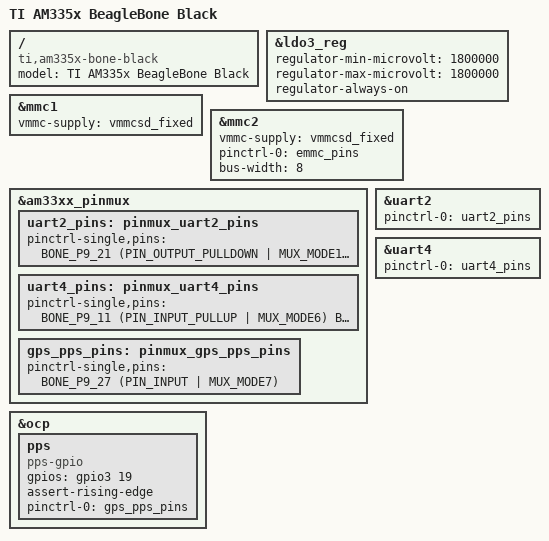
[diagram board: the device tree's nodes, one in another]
/dts-v1/;

#include "am33xx.dtsi"
#include "am335x-bone-common.dtsi"
#include <dt-bindings/board/am335x-bbw-bbb-base.h>
#include <dt-bindings/pinctrl/am33xx.h>

/ {
	model = "TI AM335x BeagleBone Black";
	compatible = "ti,am335x-bone-black", "ti,am335x-bone", "ti,am33xx";
};

&ldo3_reg {
	regulator-min-microvolt = <1800000>;
	regulator-max-microvolt = <1800000>;
	regulator-always-on;
};

&mmc1 {
	vmmc-supply = <&vmmcsd_fixed>;
};

&mmc2 {
	vmmc-supply = <&vmmcsd_fixed>;
	pinctrl-names = "default";
	pinctrl-0 = <&emmc_pins>;
	bus-width = <8>;
	status = "okay";
};

&am33xx_pinmux {

	uart2_pins: pinmux_uart2_pins {
		pinctrl-single,pins = <
			BONE_P9_21 (PIN_OUTPUT_PULLDOWN | MUX_MODE1) /* spi0_d0.uart2_txd */
			BONE_P9_22 (PIN_INPUT_PULLUP | MUX_MODE1) /* spi0_sclk.uart2_rxd */
			BONE_P8_38 (PIN_OUTPUT | MUX_MODE6)	/* lcd_data9.uart2_rtsn */
			BONE_P8_37 (PIN_INPUT  | MUX_MODE6)	/* lcd_data8.uart2_ctsn */
		>;
	};

	uart4_pins: pinmux_uart4_pins {
		pinctrl-single,pins = <
			BONE_P9_11 (PIN_INPUT_PULLUP | MUX_MODE6) /* P9_11: gpmc_wait0.uart4_rxd_mux2 */
			BONE_P9_13 (PIN_OUTPUT_PULLDOWN | MUX_MODE6) /* P9_13: gpmc_wpn.uart4_txd_mux2  */
		>;
	};

	gps_pps_pins: pinmux_gps_pps_pins {
		pinctrl-single,pins = <
			BONE_P9_27 (PIN_INPUT | MUX_MODE7)
		>;
	};
	
};

&ocp {
	pps {
		compatible = "pps-gpio";
		gpios = <&gpio3 19 0>;
		assert-rising-edge;
		pinctrl-names = "default";
		pinctrl-0 = <&gps_pps_pins>;
		status = "okay";
	};
};

&uart2 {
	status = "okay";
	pinctrl-names = "default";
	pinctrl-0 = <&uart2_pins>;
};

&uart4 {
	status = "okay";
	pinctrl-names = "default";
	pinctrl-0 = <&uart4_pins>;
};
